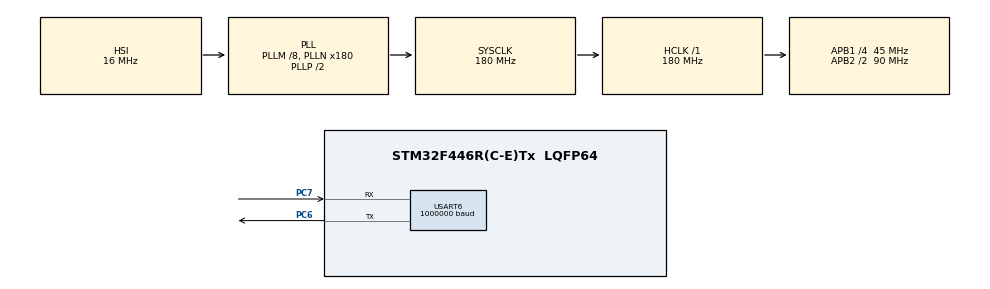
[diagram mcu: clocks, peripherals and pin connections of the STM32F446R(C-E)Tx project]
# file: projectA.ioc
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Dma.Request0=USART6_RX
Dma.Request1=USART6_TX
Dma.USART6_RX.0.Direction=DMA_PERIPH_TO_MEMORY
Dma.USART6_RX.0.FIFOMode=DMA_FIFOMODE_DISABLE
Dma.USART6_RX.0.Instance=DMA2_Stream1
Dma.USART6_RX.0.MemDataAlignment=DMA_MDATAALIGN_BYTE
Dma.USART6_RX.0.MemInc=DMA_MINC_ENABLE
Dma.USART6_RX.0.Mode=DMA_NORMAL
Dma.USART6_RX.0.PeriphDataAlignment=DMA_PDATAALIGN_BYTE
Dma.USART6_RX.0.PeriphInc=DMA_PINC_DISABLE
Dma.USART6_RX.0.Priority=DMA_PRIORITY_LOW
Dma.USART6_TX.1.Direction=DMA_MEMORY_TO_PERIPH
Dma.USART6_TX.1.FIFOMode=DMA_FIFOMODE_DISABLE
Dma.USART6_TX.1.Instance=DMA2_Stream6
Dma.USART6_TX.1.MemDataAlignment=DMA_MDATAALIGN_BYTE
Dma.USART6_TX.1.MemInc=DMA_MINC_ENABLE
Dma.USART6_TX.1.Mode=DMA_NORMAL
Dma.USART6_TX.1.PeriphDataAlignment=DMA_PDATAALIGN_BYTE
Dma.USART6_TX.1.PeriphInc=DMA_PINC_DISABLE
Dma.USART6_TX.1.Priority=DMA_PRIORITY_LOW
FREERTOS.Events01=UartEvent,Dynamic,NULL
FREERTOS.Tasks01=defaultTask,24,128,StartDefaultTask,Default,NULL,Dynamic,NULL,NULL;mainTask,8,128,mainfunc,As external,NULL,Dynamic,NULL,NULL;UART_Task,8,128,Uart_Process,As external,NULL,Dynamic,NULL,NULL
Mcu.Family=STM32F4
Mcu.Name=STM32F446R(C-E)Tx
Mcu.Package=LQFP64
NVIC.DMA2_Stream1_IRQn=true\:5\:0\:false\:false\:true\:true\:false\:true\:true
NVIC.DMA2_Stream6_IRQn=true\:5\:0\:false\:false\:true\:true\:false\:true\:true
NVIC.PriorityGroup=NVIC_PRIORITYGROUP_4
NVIC.TIM1_UP_TIM10_IRQn=true\:15\:0\:false\:false\:true\:false\:false\:true\:true
NVIC.TimeBase=TIM1_UP_TIM10_IRQn
NVIC.TimeBaseIP=TIM1
NVIC.USART6_IRQn=true\:5\:0\:false\:false\:true\:true\:true\:true\:true
PA13.Mode=Serial_Wire
PA13.Signal=SYS_JTMS-SWDIO
PA14.Mode=Serial_Wire
PA14.Signal=SYS_JTCK-SWCLK
PC6.Mode=Asynchronous
PC6.Signal=USART6_TX
PC7.Mode=Asynchronous
PC7.Signal=USART6_RX
PH0-OSC_IN.Mode=HSE-External-Oscillator
PH0-OSC_IN.Signal=RCC_OSC_IN
PH1-OSC_OUT.Mode=HSE-External-Oscillator
PH1-OSC_OUT.Signal=RCC_OSC_OUT
ProjectManager.HeapSize=0x200
ProjectManager.StackSize=0x400
ProjectManager.TargetToolchain=MDK-ARM V5.32
RCC.AHBFreq_Value=180000000
RCC.APB1CLKDivider=RCC_HCLK_DIV4
RCC.APB1Freq_Value=45000000
RCC.APB1TimFreq_Value=90000000
RCC.APB2CLKDivider=RCC_HCLK_DIV2
RCC.APB2Freq_Value=90000000
RCC.APB2TimFreq_Value=180000000
RCC.CortexFreq_Value=180000000
RCC.HCLKFreq_Value=180000000
RCC.PLLM=8
RCC.PLLN=180
RCC.SYSCLKFreq_VALUE=180000000
RCC.SYSCLKSource=RCC_SYSCLKSOURCE_PLLCLK
RCC.USBFreq_Value=180000000
RCC.VCOOutputFreq_Value=360000000
USART6.BaudRate=1000000
USART6.VirtualMode=VM_ASYNC
VP_FREERTOS_VS_CMSIS_V2.Mode=CMSIS_V2
VP_SYS_VS_tim1.Mode=TIM1
board=custom

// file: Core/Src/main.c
/* USER CODE BEGIN Header */
/**
  ******************************************************************************
  * @file           : main.c
  * @brief          : Main program body
  ******************************************************************************
  * @attention
  *
  * Copyright (c) 2025 STMicroelectronics.
  * All rights reserved.
  *
  * This software is licensed under terms that can be found in the LICENSE file
  * in the root directory of this software component.
  * If no LICENSE file comes with this software, it is provided AS-IS.
  *
  ******************************************************************************
  */
/* USER CODE END Header */
#include "main.h"
#include "cmsis_os.h"
#include "dma.h"
#include "usart.h"
#include "gpio.h"

/* USER CODE BEGIN Includes */
#include "extension.h"
/* USER CODE END Includes */

/* USER CODE BEGIN PV */
LOG_LEVEL_E g_level = LOG_LEVEL_ERROR;
/* USER CODE END PV */

void SystemClock_Config(void);
void MX_FREERTOS_Init(void);

int main(void)
{

  /* MCU Configuration--------------------------------------------------------*/

  /* Reset of all peripherals, Initializes the Flash interface and the Systick. */
  HAL_Init();

  /* Configure the system clock */
  SystemClock_Config();

  /* Initialize all configured peripherals */
  MX_GPIO_Init();
  MX_DMA_Init();
  MX_USART6_UART_Init();

  /* Init scheduler */
  osKernelInitialize();

  /* Call init function for freertos objects (in cmsis_os2.c) */
  MX_FREERTOS_Init();

  /* Start scheduler */
  osKernelStart();

  /* We should never get here as control is now taken by the scheduler */

  /* Infinite loop */
  while (1)
  {

  }
}

void SystemClock_Config(void)
{
  RCC_OscInitTypeDef RCC_OscInitStruct = {0};
  RCC_ClkInitTypeDef RCC_ClkInitStruct = {0};

  /** Configure the main internal regulator output voltage
  */
  __HAL_RCC_PWR_CLK_ENABLE();
  __HAL_PWR_VOLTAGESCALING_CONFIG(PWR_REGULATOR_VOLTAGE_SCALE1);

  /** Initializes the RCC Oscillators according to the specified parameters
  * in the RCC_OscInitTypeDef structure.
  */
  RCC_OscInitStruct.OscillatorType = RCC_OSCILLATORTYPE_HSI;
  RCC_OscInitStruct.HSIState = RCC_HSI_ON;
  RCC_OscInitStruct.HSICalibrationValue = RCC_HSICALIBRATION_DEFAULT;
  RCC_OscInitStruct.PLL.PLLState = RCC_PLL_ON;
  RCC_OscInitStruct.PLL.PLLSource = RCC_PLLSOURCE_HSI;
  RCC_OscInitStruct.PLL.PLLM = 8;
  RCC_OscInitStruct.PLL.PLLN = 180;
  RCC_OscInitStruct.PLL.PLLP = RCC_PLLP_DIV2;
  RCC_OscInitStruct.PLL.PLLQ = 2;
  RCC_OscInitStruct.PLL.PLLR = 2;
  if (HAL_RCC_OscConfig(&RCC_OscInitStruct) != HAL_OK)
  {
    Error_Handler();
  }

  /** Activate the Over-Drive mode
  */
  if (HAL_PWREx_EnableOverDrive() != HAL_OK)
  {
    Error_Handler();
  }

  /** Initializes the CPU, AHB and APB buses clocks
  */
  RCC_ClkInitStruct.ClockType = RCC_CLOCKTYPE_HCLK|RCC_CLOCKTYPE_SYSCLK
                              |RCC_CLOCKTYPE_PCLK1|RCC_CLOCKTYPE_PCLK2;
  RCC_ClkInitStruct.SYSCLKSource = RCC_SYSCLKSOURCE_PLLCLK;
  RCC_ClkInitStruct.AHBCLKDivider = RCC_SYSCLK_DIV1;
  RCC_ClkInitStruct.APB1CLKDivider = RCC_HCLK_DIV4;
  RCC_ClkInitStruct.APB2CLKDivider = RCC_HCLK_DIV2;

  if (HAL_RCC_ClockConfig(&RCC_ClkInitStruct, FLASH_LATENCY_5) != HAL_OK)
  {
    Error_Handler();
  }
}

void HAL_TIM_PeriodElapsedCallback(TIM_HandleTypeDef *htim)
{
  if (htim->Instance == TIM1) {
    HAL_IncTick();
  }
}

void Error_Handler(void)
{
  __disable_irq();
  while (1)
  {
  }
}

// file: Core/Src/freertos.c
/* USER CODE BEGIN Header */
/**
  ******************************************************************************
  * File Name          : freertos.c
  * Description        : Code for freertos applications
  ******************************************************************************
  * @attention
  *
  * Copyright (c) 2025 STMicroelectronics.
  * All rights reserved.
  *
  * This software is licensed under terms that can be found in the LICENSE file
  * in the root directory of this software component.
  * If no LICENSE file comes with this software, it is provided AS-IS.
  *
  ******************************************************************************
  */
/* USER CODE END Header */

#include "FreeRTOS.h"
#include "task.h"
#include "main.h"
#include "cmsis_os.h"

/* USER CODE BEGIN Includes */
#include "mainfunc.h"
#include "uart_task.h"
/* USER CODE END Includes */

/* Definitions for defaultTask */
osThreadId_t defaultTaskHandle;
const osThreadAttr_t defaultTask_attributes = {
  .name = "defaultTask",
  .stack_size = 128 * 4,
  .priority = (osPriority_t) osPriorityNormal,
};
/* Definitions for mainTask */
osThreadId_t mainTaskHandle;
const osThreadAttr_t mainTask_attributes = {
  .name = "mainTask",
  .stack_size = 128 * 4,
  .priority = (osPriority_t) osPriorityLow,
};
/* Definitions for UART_Task */
osThreadId_t UART_TaskHandle;
const osThreadAttr_t UART_Task_attributes = {
  .name = "UART_Task",
  .stack_size = 128 * 4,
  .priority = (osPriority_t) osPriorityLow,
};
/* Definitions for UartEvent */
osEventFlagsId_t UartEventHandle;
const osEventFlagsAttr_t UartEvent_attributes = {
  .name = "UartEvent"
};

void StartDefaultTask(void *argument);
extern void mainfunc(void *argument);
extern void Uart_Process(void *argument);

void MX_FREERTOS_Init(void); /* (MISRA C 2004 rule 8.1) */

void MX_FREERTOS_Init(void) {

  /* Create the thread(s) */
  /* creation of defaultTask */
  defaultTaskHandle = osThreadNew(StartDefaultTask, NULL, &defaultTask_attributes);

  /* creation of mainTask */
  mainTaskHandle = osThreadNew(mainfunc, NULL, &mainTask_attributes);

  /* creation of UART_Task */
  UART_TaskHandle = osThreadNew(Uart_Process, NULL, &UART_Task_attributes);

  /* Create the event(s) */
  /* creation of UartEvent */
  UartEventHandle = osEventFlagsNew(&UartEvent_attributes);

}

void StartDefaultTask(void *argument)
{
  for(;;)
  {
    osDelay(1);
  }
}
